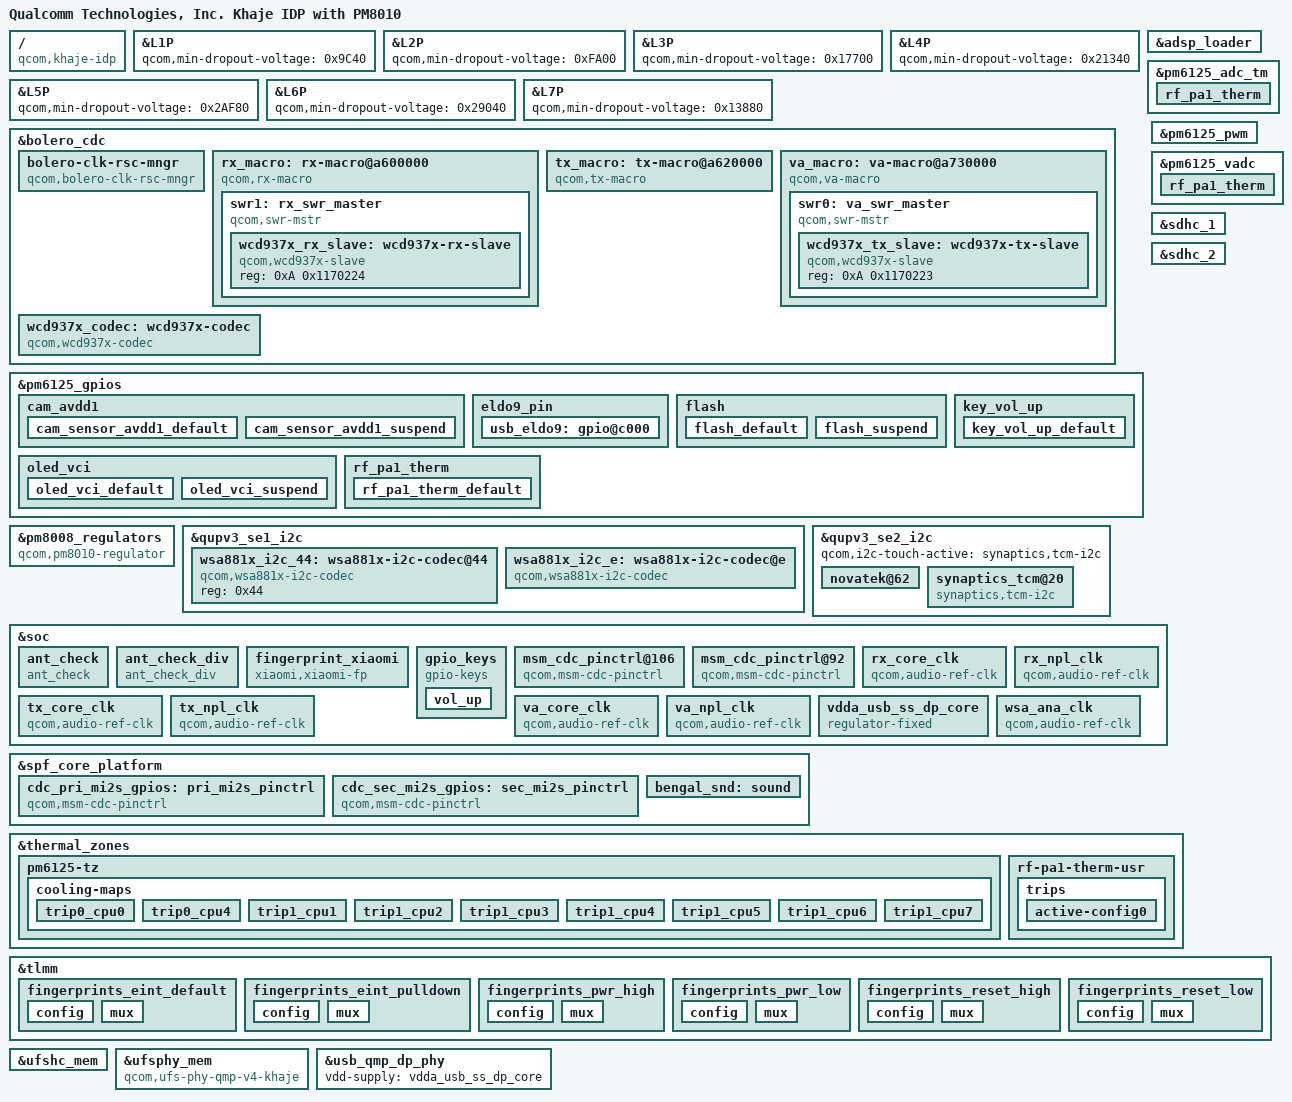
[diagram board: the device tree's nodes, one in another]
/dts-v1/;

/ {
    compatible = "qcom,khaje-idp", "qcom,khaje", "qcom,idp";
    model = "Qualcomm Technologies, Inc. Khaje IDP with PM8010";
    qcom,board-id = <0x10222 0x0>;
    qcom,msm-id = <0x24A 0x10000 0x206 0x10000>;
    qcom,pmic-id = <0x2D 0x2E 0x0 0x0>;
};

&L1P {
    qcom,min-dropout-voltage = <0x9C40>;
};

&L2P {
    qcom,min-dropout-voltage = <0xFA00>;
};

&L3P {
    qcom,min-dropout-voltage = <0x17700>;
};

&L4P {
    qcom,min-dropout-voltage = <0x21340>;
};

&L5P {
    qcom,min-dropout-voltage = <0x2AF80>;
};

&L6P {
    qcom,min-dropout-voltage = <0x29040>;
};

&L7P {
    qcom,min-dropout-voltage = <0x13880>;
};

&adsp_loader {
    adsp-fw-bit-values = <0x1>;
    adsp-fw-names = "adsp2";
    nvmem-cell-names = "adsp_variant";
    nvmem-cells = <&adsp_variant>;
};

&bolero_cdc {
    qcom,bolero-version = <0x5>;
    qcom,num-macros = <0x3>;
    bolero-clk-rsc-mngr {
        clock-names = "tx_core_clk", "tx_npl_clk", "rx_core_clk", "rx_npl_clk", "va_core_clk", "va_npl_clk";
        clocks = <&clock_audio_tx_1 0x0 &clock_audio_tx_2 0x0 &clock_audio_rx_1 0x0 &clock_audio_rx_2 0x0 &clock_audio_va_1 0x0 &clock_audio_va_2 0x0>;
        compatible = "qcom,bolero-clk-rsc-mngr";
        qcom,fs-gen-sequence = <0x3000 0x1 0x1 0x3004 0x3 0x3 0x3004 0x3 0x1 0x3080 0x2 0x2>;
        qcom,rx_mclk_mode_muxsel = <0xA5640D8>;
        qcom,va_mclk_mode_muxsel = "\nz";
    };
    rx_macro: rx-macro@a600000 {
        clock-names = "rx_core_clk", "rx_npl_clk";
        clocks = <&clock_audio_rx_1 0x0 &clock_audio_rx_2 0x0>;
        compatible = "qcom,rx-macro";
        qcom,default-clk-id = <0x0>;
        qcom,rx-bcl-pmic-params = [00 04 3E];
        qcom,rx-swr-gpios = <&rx_swr_gpios>;
        qcom,rx_mclk_mode_muxsel = <0xA5640D8>;
        reg = <0xA600000 0x0>;
        swr1: rx_swr_master {
            #address-cells = <0x2>;
            #size-cells = <0x0>;
            clock-names = "lpass_audio_hw_vote";
            clocks = <&lpass_audio_hw_vote 0x0>;
            compatible = "qcom,swr-mstr";
            interrupt-names = "swr_master_irq";
            interrupts = <0x0 0x129 0x4>;
            qcom,disable-div2-clk-switch = <0x1>;
            qcom,mipi-sdw-block-packing-mode = <0x1>;
            qcom,swr-clock-stop-mode0 = <0x1>;
            qcom,swr-master-version = <0x1060000>;
            qcom,swr-num-dev = <0x1>;
            qcom,swr-num-ports = <0x5>;
            qcom,swr-port-mapping = <0x1 0xE 0x1 0x1 0xF 0x2 0x2 0x12 0x1 0x3 0x10 0x1 0x3 0x11 0x2 0x4 0x13 0x1 0x5 0x14 0x1 0x5 0x15 0x2>;
            qcom,swr_master_id = <0x2>;
            qcom,swrm-hctl-reg = <0xA6A9098>;
            swrm-io-base = <0xA610000 0x0>;
            wcd937x_rx_slave: wcd937x-rx-slave {
                compatible = "qcom,wcd937x-slave";
                reg = <0xA 0x1170224>;
            };
        };
    };
    tx_macro: tx-macro@a620000 {
        clock-names = "tx_core_clk", "tx_npl_clk";
        clocks = <&clock_audio_tx_1 0x0 &clock_audio_tx_2 0x0>;
        compatible = "qcom,tx-macro";
        qcom,is-used-swr-gpio = <0x0>;
        qcom,tx-dmic-sample-rate = <0x249F00>;
        reg = <0xA620000 0x0>;
    };
    va_macro: va-macro@a730000 {
        clock-names = "lpass_audio_hw_vote";
        clocks = <&lpass_audio_hw_vote 0x0>;
        compatible = "qcom,va-macro";
        qcom,default-clk-id = <0x0>;
        qcom,is-used-swr-gpio = <0x1>;
        qcom,va-clk-mux-select = <0x1>;
        qcom,va-dmic-sample-rate = <0x927C0>;
        qcom,va-island-mode-muxsel = "\nz";
        qcom,va-swr-gpios = <&va_swr_gpios>;
        reg = <0xA730000 0x0>;
        swr0: va_swr_master {
            #address-cells = <0x2>;
            #size-cells = <0x0>;
            clock-names = "lpass_audio_hw_vote";
            clocks = <&lpass_audio_hw_vote 0x0>;
            compatible = "qcom,swr-mstr";
            interrupt-names = "swr_master_irq", "swr_wake_irq";
            interrupts = <0x0 0x128 0x4 0x0 0x4F 0x4>;
            qcom,is-always-on = <0x1>;
            qcom,mipi-sdw-block-packing-mode = <0x1>;
            qcom,swr-clock-stop-mode0 = <0x1>;
            qcom,swr-master-version = <0x1060000>;
            qcom,swr-mstr-irq-wakeup-capable = <0x1>;
            qcom,swr-num-dev = <0x1>;
            qcom,swr-num-ports = <0x3>;
            qcom,swr-port-mapping = <0x1 0x2E 0x1 0x1 0x2F 0x2 0x1 0x30 0x4 0x1 0x31 0x8 0x2 0x32 0x1 0x2 0x33 0x2 0x2 0x34 0x4 0x2 0x35 0x8 0x3 0x36 0x1 0x3 0x37 0x2 0x3 0x38 0x4 0x3 0x39 0x8>;
            qcom,swr-wakeup-required = <0x1>;
            qcom,swr_master_id = <0x3>;
            qcom,swrm-hctl-reg = <0xA7EC100>;
            swrm-io-base = <0xA740000 0x0>;
            wcd937x_tx_slave: wcd937x-tx-slave {
                compatible = "qcom,wcd937x-slave";
                reg = <0xA 0x1170223>;
            };
        };
    };
    wcd937x_codec: wcd937x-codec {
        cdc-vdd-buck-supply = <&L14A>;
        cdc-vdd-rxtx-supply = <&L9A>;
        cdc-vddpx-supply = <&L9A>;
        compatible = "qcom,wcd937x-codec";
        qcom,cdc-micbias1-mv = <0x708>;
        qcom,cdc-micbias2-mv = <0x708>;
        qcom,cdc-micbias3-mv = <0x708>;
        qcom,cdc-on-demand-supplies = "cdc-vdd-buck";
        qcom,cdc-static-supplies = "cdc-vdd-rxtx", "cdc-vddpx";
        qcom,cdc-vdd-buck-current = <0x9EB10>;
        qcom,cdc-vdd-buck-voltage = <0x1B7740 0x1B7740>;
        qcom,cdc-vdd-rxtx-current = <0x2710>;
        qcom,cdc-vdd-rxtx-voltage = <0x1B7740 0x1B7740>;
        qcom,cdc-vddpx-current = <0x4E20>;
        qcom,cdc-vddpx-voltage = <0x1B7740 0x1B7740>;
        qcom,rx-slave = <&wcd937x_rx_slave>;
        qcom,rx_swr_ch_map = <0x0 0xE 0x1 0x0 0xE 0x0 0xF 0x2 0x0 0xF 0x1 0x12 0x1 0x0 0x12 0x2 0x10 0x1 0x0 0x10 0x2 0x11 0x2 0x0 0x11 0x3 0x13 0x1 0x0 0x13 0x4 0x14 0x1 0x0 0x14 0x4 0x15 0x2 0x0 0x15>;
        qcom,split-codec = <0x1>;
        qcom,swr-tx-port-params = <0x1 0x0 0x0 0x1 0x1 0x0 0x1 0x0 0x0 0x1 0x1 0x0 0x1 0x0 0x1 0x0 0x0 0x1 0x2 0x0 0x1 0x0 0x2 0x0 0x1 0x0 0x1 0x0 0x1 0x0 0x1 0x0>;
        qcom,tx-slave = <&wcd937x_tx_slave>;
        qcom,tx_swr_ch_map = <0x0 0x1E 0x1 0x493E00 0x2E 0x1 0x1F 0x1 0x493E00 0x32 0x1 0x20 0x2 0x493E00 0x33 0x2 0x22 0x1 0x0 0x31 0x2 0x23 0x2 0x0 0x32 0x2 0x1D 0x4 0x493E00 0x33 0x3 0x24 0x1 0x0 0x34 0x3 0x25 0x2 0x0 0x35 0x3 0x26 0x4 0x0 0x36 0x3 0x27 0x8 0x0 0x37>;
        qcom,wcd-rst-gpio-node = <&wcd937x_rst_gpio>;
    };
};

&pm6125_adc_tm {
    status = "ok";
    rf_pa1_therm {
        io-channels = <&pm6125_vadc 0x55>;
        qcom,hw-settle-time-us = <0xC8>;
        qcom,ratiometric;
        reg = <0x3>;
    };
};

&pm6125_gpios {
    cam_avdd1 {
        cam_sensor_avdd1_default: cam_sensor_avdd1_default {
            bias-disable;
            function = "normal";
            pins = "gpio2";
            power-source = <0x0>;
            qcom,drive-strength = <0x2>;
        };
        cam_sensor_avdd1_suspend: cam_sensor_avdd1_suspend {
            bias-disable;
            function = "normal";
            output-low;
            pins = "gpio2";
            power-source = <0x0>;
            qcom,drive-strength = <0x2>;
        };
    };
    eldo9_pin {
        usb_eldo9: gpio@c000 {
            bias-disable;
            function = "normal";
            output-high;
            pins = "gpio1";
            power-source = <0x0>;
            qcom,drive-strength = <0x2>;
        };
    };
    flash {
        flash_default: flash_default {
            bias-pull-up;
            function = "normal";
            output-high;
            pins = "gpio8";
            power-source = <0x1>;
            qcom,drive-strength = <0x2>;
        };
        flash_suspend: flash_suspend {
            bias-disable;
            function = "normal";
            output-low;
            pins = "gpio8";
            power-source = <0x1>;
            qcom,drive-strength = <0x2>;
        };
    };
    key_vol_up {
        key_vol_up_default: key_vol_up_default {
            bias-pull-up;
            function = "normal";
            input-enable;
            pins = "gpio5";
            power-source = <0x0>;
        };
    };
    oled_vci {
        oled_vci_default: oled_vci_default {
            bias-disable;
            function = "normal";
            input-disable;
            output-high;
            pins = "gpio9";
            power-source = <0x0>;
            qcom,drive-strength = <0x2>;
        };
        oled_vci_suspend: oled_vci_suspend {
            bias-disable;
            function = "normal";
            input-disable;
            output-low;
            pins = "gpio9";
            power-source = <0x0>;
            qcom,drive-strength = <0x2>;
        };
    };
    rf_pa1_therm {
        rf_pa1_therm_default: rf_pa1_therm_default {
            bias-high-impedance;
            pins = "gpio7";
        };
    };
};

&pm6125_pwm {
    status = "ok";
};

&pm6125_vadc {
    pinctrl-0 = <&camera_therm_default &emmc_therm_default &rf_pa1_therm_default>;
    rf_pa1_therm {
        label = "rf_pa1_therm";
        qcom,hw-settle-time = <0xC8>;
        qcom,pre-scaling = <0x1 0x1>;
        qcom,ratiometric;
        reg = <0x55>;
    };
};

&pm8008_regulators {
    compatible = "qcom,pm8010-regulator";
};

&qupv3_se1_i2c {
    wsa881x_i2c_44: wsa881x-i2c-codec@44 {
        compatible = "qcom,wsa881x-i2c-codec";
        reg = <0x44>;
    };
    wsa881x_i2c_e: wsa881x-i2c-codec@e {
        clock-names = "wsa_mclk";
        clocks = <&wsa881x_analog_clk 0x0>;
        compatible = "qcom,wsa881x-i2c-codec";
        qcom,wsa-analog-clk-gpio = <&wsa881x_analog_clk_gpio>;
        qcom,wsa-analog-reset-gpio = <&wsa881x_analog_reset_gpio>;
        qcom,wsa-prefix = "SpkrMono";
        reg = <0xE>;
    };
};

&qupv3_se2_i2c {
    qcom,i2c-touch-active = "synaptics,tcm-i2c";
    status = "okay";
    novatek@62 {
        interrupt-parent = <&tlmm>;
        interrupts = <0x50 0x2008>;
        novatek,irq-gpio = <&tlmm 0x50 0x2008>;
        novatek,reset-gpio = <&tlmm 0x56 0x0>;
        pinctrl-0 = <&ts_int_active &ts_reset_active>;
        pinctrl-1 = <&ts_int_suspend &ts_reset_suspend>;
        pinctrl-2 = <&ts_release>;
        pinctrl-names = "pmx_ts_active", "pmx_ts_suspend", "pmx_ts_release";
        reg = <0x62>;
        status = "ok";
    };
    synaptics_tcm@20 {
        compatible = "synaptics,tcm-i2c";
        interrupt-parent = <&tlmm>;
        interrupts = <0x50 0x2008>;
        pinctrl-0 = <&ts_int_active &ts_reset_active>;
        pinctrl-1 = <&ts_int_suspend &ts_reset_suspend>;
        pinctrl-2 = <&ts_release>;
        pinctrl-names = "pmx_ts_active", "pmx_ts_suspend", "pmx_ts_release";
        reg = <0x20>;
        synaptics,extend_report;
        synaptics,firmware-name = "synaptics_firmware_k.img";
        synaptics,irq-gpio = <&tlmm 0x50 0x2008>;
        synaptics,irq-on-state = <0x0>;
        synaptics,power-delay-ms = <0xC8>;
        synaptics,reset-active-ms = <0x14>;
        synaptics,reset-delay-ms = <0xC8>;
        synaptics,reset-gpio = <&tlmm 0x56 0x0>;
        synaptics,reset-on-state = <0x0>;
        synaptics,ubl-i2c-addr = <0x20>;
    };
};

&sdhc_1 {
    pinctrl-0 = <&sdc1_on>;
    pinctrl-1 = <&sdc1_off>;
    pinctrl-names = "default", "sleep";
    qcom,vdd-current-level = <0x0 0x8B290>;
    qcom,vdd-io-always-on;
    qcom,vdd-io-current-level = <0x0 0x4F588>;
    qcom,vdd-io-lpm-sup;
    qcom,vdd-io-voltage-level = <0x1B7740 0x1B7740>;
    qcom,vdd-voltage-level = <0x2D2A80 0x2D2A80>;
    status = "ok";
    vdd-io-supply = <&L11A>;
    vdd-supply = <&L24A>;
};

&sdhc_2 {
    cd-gpios = <&tlmm 0x58 0x1>;
    pinctrl-0 = <&sdc2_on>;
    pinctrl-1 = <&sdc2_off>;
    pinctrl-names = "default", "sleep";
    qcom,vdd-current-level = <0x0 0xC3500>;
    qcom,vdd-io-bias-current-level = <0x0 0x1770>;
    qcom,vdd-io-bias-voltage-level = <0x132A40 0x132A40>;
    qcom,vdd-io-current-level = <0x0 0x55F0>;
    qcom,vdd-io-voltage-level = <0x1B7740 0x2D2A80>;
    qcom,vdd-voltage-level = <0x2D2A80 0x2D2A80>;
    status = "ok";
    vdd-io-bias-supply = <&L7A>;
    vdd-io-supply = <&L5A>;
    vdd-supply = <&L22A>;
};

&soc {
    ant_check {
        ant_check_gpio = <&tlmm 0x6B 0x0>;
        compatible = "ant_check";
        interrupt-parent = <&tlmm>;
        pinctrl-0 = <&ant_check_default>;
        pinctrl-names = "default";
    };
    ant_check_div {
        ant_check_div_gpio = <&tlmm 0x19 0x0>;
        compatible = "ant_check_div";
        interrupt-parent = <&tlmm>;
        pinctrl-0 = <&ant_check_div_default>;
        pinctrl-names = "default";
    };
    fingerprint_xiaomi {
        compatible = "xiaomi,xiaomi-fp";
        fp-gpio-pwr = <&tlmm 0x41 0x0>;
        netlink-event = <0x1D>;
        pinctrl-0 = <&fingerprints_reset_high>;
        pinctrl-1 = <&fingerprints_reset_low>;
        pinctrl-2 = <&fingerprints_eint_default>;
        pinctrl-3 = <&fingerprints_eint_pulldown>;
        pinctrl-4 = <&fingerprints_pwr_high>;
        pinctrl-5 = <&fingerprints_pwr_low>;
        pinctrl-names = "reset_high", "reset_low", "eint_default", "eint_pulldown", "pwr_high", "pwr_low";
        status = "okay";
        vfp-supply = <&pm6125_l9>;
        xiaomi,gpio_irq = <&tlmm 0x53 0x0>;
    };
    gpio_keys {
        compatible = "gpio-keys";
        label = "gpio-keys";
        pinctrl-0 = <&key_vol_up_default>;
        pinctrl-names = "default";
        vol_up {
            debounce-interval = <0xF>;
            gpio-key,wakeup;
            gpios = <&pm6125_gpios 0x5 0x1>;
            label = "volume_up";
            linux,can-disable;
            linux,code = <0x73>;
            linux,input-type = <0x1>;
        };
    };
    msm_cdc_pinctrl@106 {
        #gpio-cells = <0x0>;
        compatible = "qcom,msm-cdc-pinctrl";
        pinctrl-0 = <&spkr_1_sd_n_active>;
        pinctrl-1 = <&spkr_1_sd_n_sleep>;
        pinctrl-names = "aud_active", "aud_sleep";
    };
    msm_cdc_pinctrl@92 {
        #gpio-cells = <0x0>;
        compatible = "qcom,msm-cdc-pinctrl";
        pinctrl-0 = <&wcd937x_reset_active>;
        pinctrl-1 = <&wcd937x_reset_sleep>;
        pinctrl-names = "aud_active", "aud_sleep";
    };
    rx_core_clk {
        #clock-cells = <0x1>;
        compatible = "qcom,audio-ref-clk";
        qcom,codec-ext-clk-src = <0x5>;
        qcom,codec-lpass-clk-id = <0x30E>;
        qcom,codec-lpass-ext-clk-freq = <0x1588800>;
    };
    rx_npl_clk {
        #clock-cells = <0x1>;
        compatible = "qcom,audio-ref-clk";
        qcom,codec-ext-clk-src = <0x6>;
        qcom,codec-lpass-clk-id = <0x30F>;
        qcom,codec-lpass-ext-clk-freq = <0x1588800>;
    };
    tx_core_clk {
        #clock-cells = <0x1>;
        compatible = "qcom,audio-ref-clk";
        qcom,codec-ext-clk-src = <0x7>;
        qcom,codec-lpass-clk-id = <0x30C>;
        qcom,codec-lpass-ext-clk-freq = <0x124F800>;
    };
    tx_npl_clk {
        #clock-cells = <0x1>;
        compatible = "qcom,audio-ref-clk";
        qcom,codec-ext-clk-src = <0x8>;
        qcom,codec-lpass-clk-id = <0x30D>;
        qcom,codec-lpass-ext-clk-freq = <0x124F800>;
    };
    va_core_clk {
        #clock-cells = <0x1>;
        compatible = "qcom,audio-ref-clk";
        qcom,codec-ext-clk-src = <0x2>;
        qcom,codec-lpass-clk-id = <0x307>;
        qcom,codec-lpass-ext-clk-freq = <0x124F800>;
    };
    va_npl_clk {
        #clock-cells = <0x1>;
        compatible = "qcom,audio-ref-clk";
        qcom,codec-ext-clk-src = <0xA>;
        qcom,codec-lpass-clk-id = <0x308>;
        qcom,codec-lpass-ext-clk-freq = <0x124F800>;
    };
    vdda_usb_ss_dp_core {
        compatible = "regulator-fixed";
        enable-active-high;
        gpio = <&pm6125_gpios 0x1 0x0>;
        pinctrl-0 = <&usb_eldo9>;
        pinctrl-names = "default";
        regulator-max-microvolt = <0xD6D80>;
        regulator-min-microvolt = <0xD6D80>;
        regulator-name = "vdd_supply";
    };
    wsa_ana_clk {
        #clock-cells = <0x1>;
        compatible = "qcom,audio-ref-clk";
        qcom,codec-ext-clk-src = <0x3>;
        qcom,codec-lpass-clk-id = <0x301>;
        qcom,codec-lpass-ext-clk-freq = <0x927C00>;
    };
};

&spf_core_platform {
    cdc_pri_mi2s_gpios: pri_mi2s_pinctrl {
        #gpio-cells = <0x0>;
        compatible = "qcom,msm-cdc-pinctrl";
        pinctrl-0 = <&lpi_i2s1_sck_active &lpi_i2s1_ws_active &lpi_i2s1_sd0_active &lpi_i2s1_sd1_active>;
        pinctrl-1 = <&lpi_i2s1_sck_sleep &lpi_i2s1_ws_sleep &lpi_i2s1_sd0_sleep &lpi_i2s1_sd1_sleep>;
        pinctrl-names = "aud_active", "aud_sleep";
        qcom,lpi-gpios;
    };
    cdc_sec_mi2s_gpios: sec_mi2s_pinctrl {
        #gpio-cells = <0x0>;
        compatible = "qcom,msm-cdc-pinctrl";
        pinctrl-0 = <&lpi_i2s2_sck_active &lpi_i2s2_ws_active &lpi_i2s2_sd0_active &lpi_i2s2_sd1_active>;
        pinctrl-1 = <&lpi_i2s2_sck_sleep &lpi_i2s2_ws_sleep &lpi_i2s2_sd0_sleep &lpi_i2s2_sd1_sleep>;
        pinctrl-names = "aud_active", "aud_sleep";
        qcom,lpi-gpios;
    };
    bengal_snd: sound {
        asoc-codec = <&stub_codec &bolero_cdc &wcd937x_codec &wsa881x_i2c_e>;
        asoc-codec-names = "msm-stub-codec.1", "bolero-codec", "wcd937x_codec", "wsa-codec0";
        nvmem-cell-names = "adsp_variant";
        nvmem-cells = <&adsp_variant>;
        qcom,audio-routing = "AMIC1", "Analog Mic1", "AMIC1", "MIC BIAS1", "AMIC2", "Analog Mic2", "AMIC2", "MIC BIAS2", "AMIC3", "Analog Mic3", "AMIC3", "MIC BIAS3", "TX DMIC0", "Digital Mic0", "TX DMIC0", "MIC BIAS1", "TX DMIC1", "Digital Mic1", "TX DMIC1", "MIC BIAS1", "TX DMIC2", "Digital Mic2", "TX DMIC2", "MIC BIAS3", "TX DMIC3", "Digital Mic3", "TX DMIC3", "MIC BIAS3", "IN1_HPHL", "HPHL_OUT", "IN2_HPHR", "HPHR_OUT", "IN3_AUX", "AUX_OUT", "RX_TX DEC0_INP", "TX DEC0 MUX", "RX_TX DEC1_INP", "TX DEC1 MUX", "RX_TX DEC2_INP", "TX DEC2 MUX", "RX_TX DEC3_INP", "TX DEC3 MUX", "SpkrMono WSA_IN", "AUX", "TX SWR_INPUT", "WCD_TX_OUTPUT", "VA SWR_INPUT", "VA_SWR_CLK", "VA SWR_INPUT", "WCD_TX_OUTPUT", "TX_AIF1 CAP", "VA_SWR_CLK", "TX_AIF2 CAP", "VA_SWR_CLK", "TX_AIF3 CAP", "VA_SWR_CLK", "VA DMIC0", "Digital Mic0", "VA DMIC1", "Digital Mic1", "VA DMIC2", "Digital Mic2", "VA DMIC3", "Digital Mic3", "VA DMIC0", "VA MIC BIAS1", "VA DMIC1", "VA MIC BIAS1", "VA DMIC2", "VA MIC BIAS3", "VA DMIC3", "VA MIC BIAS3";
        qcom,cdc-dmic01-gpios = <&cdc_dmic01_gpios>;
        qcom,cdc-dmic23-gpios = <&cdc_dmic23_gpios>;
        qcom,model = "bengal-idp-snd-card";
        qcom,msm-mbhc-gnd-swh = <0x1>;
        qcom,msm-mbhc-hphl-swh = <0x1>;
        qcom,msm-mbhc-usbc-audio-supported = <0x0>;
        qcom,msm-mi2s-master = <0x1 0x1 0x1 0x1>;
        qcom,msm_audio_ssr_devs = <&audio_gpr &lpi_tlmm &bolero_cdc>;
        qcom,rxtx-bolero-codec = <0x1>;
        qcom,va-bolero-codec = <0x1>;
        qcom,wcn-btfm = <0x1>;
        qcom,wsa-aux-dev-prefix = "SpkrMono";
        qcom,wsa-max-devs = <0x1>;
    };
};

&thermal_zones {
    pm6125-tz {
        cooling-maps {
            trip0_cpu0 {
                cooling-device = <&CPU0 0x7 0x7>;
                trip = <&pm6125_trip0>;
            };
            trip0_cpu4 {
                cooling-device = <&CPU4 0x6 0xFFFFFFFF>;
                trip = <&pm6125_trip0>;
            };
            trip1_cpu1 {
                cooling-device = <&cpu1_pause 0x1 0x1>;
                trip = <&pm6125_trip1>;
            };
            trip1_cpu2 {
                cooling-device = <&cpu2_pause 0x1 0x1>;
                trip = <&pm6125_trip1>;
            };
            trip1_cpu3 {
                cooling-device = <&cpu3_pause 0x1 0x1>;
                trip = <&pm6125_trip1>;
            };
            trip1_cpu4 {
                cooling-device = <&cpu4_pause 0x1 0x1>;
                trip = <&pm6125_trip1>;
            };
            trip1_cpu5 {
                cooling-device = <&cpu5_pause 0x1 0x1>;
                trip = <&pm6125_trip1>;
            };
            trip1_cpu6 {
                cooling-device = <&cpu6_pause 0x1 0x1>;
                trip = <&pm6125_trip1>;
            };
            trip1_cpu7 {
                cooling-device = <&cpu7_pause 0x1 0x1>;
                trip = <&pm6125_trip1>;
            };
        };
    };
    rf-pa1-therm-usr {
        polling-delay = <0x0>;
        polling-delay-passive = <0x0>;
        thermal-governor = "user_space";
        thermal-sensors = <&pm6125_adc_tm 0x3>;
        wake-capable-sensor;
        trips {
            active-config0 {
                hysteresis = <0x3E8>;
                temperature = <0x1E848>;
                type = "passive";
            };
        };
    };
};

&tlmm {
    fingerprints_eint_default: fingerprints_eint_default {
        config {
            bias-disable;
            drive-strength = <0x2>;
            pins = "gpio83";
        };
        mux {
            function = "gpio";
            pins = "gpio83";
        };
    };
    fingerprints_eint_pulldown: fingerprints_eint_pulldown {
        config {
            bias-pull-down;
            drive-strength = <0x2>;
            pins = "gpio83";
        };
        mux {
            function = "gpio";
            pins = "gpio83";
        };
    };
    fingerprints_pwr_high: fingerprints_pwr_high {
        config {
            bias-disable;
            drive-strength = <0x2>;
            output-high;
            pins = "gpio65";
        };
        mux {
            function = "gpio";
            pins = "gpio65";
        };
    };
    fingerprints_pwr_low: fingerprints_pwr_low {
        config {
            bias-disable;
            drive-strength = <0x2>;
            output-high;
            pins = "gpio65";
        };
        mux {
            function = "gpio";
            pins = "gpio65";
        };
    };
    fingerprints_reset_high: fingerprints_reset_high {
        config {
            bias-disable;
            drive-strength = <0x2>;
            output-high;
            pins = "gpio104";
        };
        mux {
            function = "gpio";
            pins = "gpio104";
        };
    };
    fingerprints_reset_low: fingerprints_reset_low {
        config {
            bias-disable;
            drive-strength = <0x2>;
            output-low;
            pins = "gpio104";
        };
        mux {
            function = "gpio";
            pins = "gpio104";
        };
    };
};

&ufshc_mem {
    qcom,vddp-ref-clk-max-microamp = <0x64>;
    qcom,vddp-ref-clk-supply = <&L18A>;
    reset-gpios = <&tlmm 0x71 0x1>;
    reset-names = "rst";
    resets = <&gcc 0x4>;
    status = "ok";
    vcc-max-microamp = "\f5";
    vcc-supply = <&L24A>;
    vccq2-max-microamp = "\f5";
    vccq2-supply = <&L11A>;
    vdd-hba-fixed-regulator;
    vdd-hba-supply = <&gcc_ufs_phy_gdsc>;
};

&ufsphy_mem {
    compatible = "qcom,ufs-phy-qmp-v4-khaje";
    status = "ok";
    vdda-phy-max-microamp = <0x14EC4>;
    vdda-phy-supply = <&L4A>;
    vdda-pll-max-microamp = <0x477C>;
    vdda-pll-supply = <&L18A>;
};

&usb_qmp_dp_phy {
    vdd-supply = <&vdda_usb_ss_dp_core>;
};

